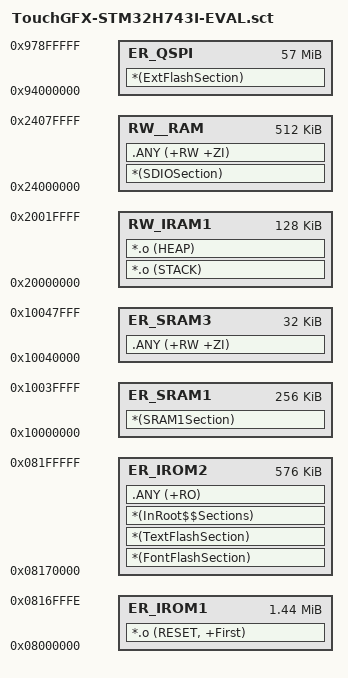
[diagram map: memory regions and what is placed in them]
; *************************************************************
; *** Scatter-Loading Description File generated by uVision ***
; *************************************************************

LR_IROM1 0x08000000  0x16FFFF {    
  ER_IROM1 0x08000000  0x16FFFF {  
   *.o (RESET, +First)
   }
  RW_IRAM1 0x20000000 0x20000  {  ; only HEAD and STACK
     *.o (STACK)
	 *.o (HEAP)
	}   
}
  
LR_IROM2 0x08170000  0x90000 {    
  ER_IROM2 0x08170000 0x90000 {  
   *(FontFlashSection)
   *(TextFlashSection)
   *(InRoot$$Sections)
   .ANY (+RO)
  }  
  RW__RAM 0x24000000 0x80000 {  
   *(SDIOSection)
   .ANY (+RW +ZI)
  }  
  ER_SRAM1 0x10000000 0x40000 {  
   *(SRAM1Section)
  }
  ER_SRAM3 0x10040000 0x8000 {  
   .ANY (+RW +ZI)
  }
}
  
LR_QSPI 0x94000000 0x3900000 {
	ER_QSPI  0x94000000 0x3900000{
	*(ExtFlashSection)
	}
}
